# CY8C5888LTI_LP097 register map
File version: 0.1
CY8C58LP
Registers are 8-bit, read-write, no defined reset value unless marked. A register's access mark holds for its fields unless they carry their own. Offsets are from the block's base; lines under a group give offsets from that group; [hi:lo] are bit positions; {n}, {i} and the like mark numbered series; 'fields as' and 'values as' point back to an identical list; <NAME> marks a mode.

## Memory map
0x00000000 USBMIDI_1 — USBFS
0x00000000 MIDI1_UART — UART
0x40006470 Control_Reg_4
0x40006471 Control_Reg_1
0x40006472 Control_Reg_5
0x40006475 Control_Reg_3
0x40006476 Control_Reg_7
0x40006477 Control_Reg_15
0x40006478 Control_Reg_12
0x40006479 Control_Reg_14
0x4000647B Control_Reg_10
0x4000647C Control_Reg_8
0x4000647D Control_Reg_16
0x4000647E Control_Reg_2
0x4000647F Control_Reg_6
0x40006574 Control_Reg_13
0x40006575 Control_Reg_9
0x40006576 Control_Reg_11

## Control_Reg_13
Base 0x40006574
0x00 Control_Reg_13_CONTROL_REG

## Control_Reg_12
Base 0x40006478
Registers as Control_Reg_13 (with Control_Reg_13 read as Control_Reg_12).

## Control_Reg_15
Base 0x40006477
Registers as Control_Reg_13 (with Control_Reg_13 read as Control_Reg_15).

## Control_Reg_14
Base 0x40006479
Registers as Control_Reg_13 (with Control_Reg_13 read as Control_Reg_14).

## Control_Reg_9
Base 0x40006575
Registers as Control_Reg_13 (with Control_Reg_13 read as Control_Reg_9).

## Control_Reg_8
Base 0x4000647C
Registers as Control_Reg_13 (with Control_Reg_13 read as Control_Reg_8).

## Control_Reg_11
Base 0x40006576
Registers as Control_Reg_13 (with Control_Reg_13 read as Control_Reg_11).

## Control_Reg_10
Base 0x4000647B
Registers as Control_Reg_13 (with Control_Reg_13 read as Control_Reg_10).

## Control_Reg_16
Base 0x4000647D
Registers as Control_Reg_13 (with Control_Reg_13 read as Control_Reg_16).

## Control_Reg_1
Base 0x40006471
Registers as Control_Reg_13 (with Control_Reg_13 read as Control_Reg_1).

## Control_Reg_4
Base 0x40006470
Registers as Control_Reg_13 (with Control_Reg_13 read as Control_Reg_4).

## Control_Reg_3
Base 0x40006475
Registers as Control_Reg_13 (with Control_Reg_13 read as Control_Reg_3).

## Control_Reg_2
Base 0x4000647E
Registers as Control_Reg_13 (with Control_Reg_13 read as Control_Reg_2).

## Control_Reg_5
Base 0x40006472
Registers as Control_Reg_13 (with Control_Reg_13 read as Control_Reg_5).

## Control_Reg_7
Base 0x40006476
Registers as Control_Reg_13 (with Control_Reg_13 read as Control_Reg_7).

## Control_Reg_6
Base 0x4000647F
Registers as Control_Reg_13 (with Control_Reg_13 read as Control_Reg_6).

## MIDI1_UART — UART
Base 0x00000000
0x40006423 RX_MIDI1_UART_RX_ADDRESS1 — RX Address1 Register
0x40006433 RX_MIDI1_UART_RX_ADDRESS2 — RX Address2 Register
0x40006443 RX_MIDI1_UART_RX_DATA — RX Data Register
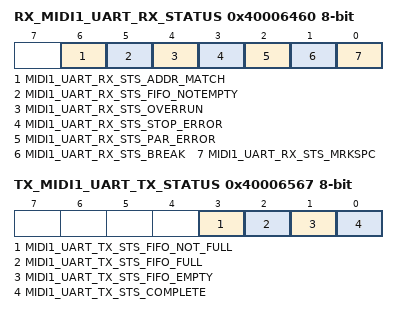
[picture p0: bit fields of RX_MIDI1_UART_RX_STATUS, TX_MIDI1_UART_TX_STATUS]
0x40006460 RX_MIDI1_UART_RX_STATUS — RX status register
  [6] MIDI1_UART_RX_STS_ADDR_MATCH ro, [5] MIDI1_UART_RX_STS_FIFO_NOTEMPTY ro, [4] MIDI1_UART_RX_STS_OVERRUN ro, [3] MIDI1_UART_RX_STS_STOP_ERROR ro, [2] MIDI1_UART_RX_STS_PAR_ERROR ro, [1] MIDI1_UART_RX_STS_BREAK ro, [0] MIDI1_UART_RX_STS_MRKSPC ro
0x40006544 TX_MIDI1_UART_TX_DATA — TX Data Register
0x40006567 TX_MIDI1_UART_TX_STATUS — TX status register
  [3] MIDI1_UART_TX_STS_FIFO_NOT_FULL ro, [2] MIDI1_UART_TX_STS_FIFO_FULL ro, [1] MIDI1_UART_TX_STS_FIFO_EMPTY ro, [0] MIDI1_UART_TX_STS_COMPLETE ro
